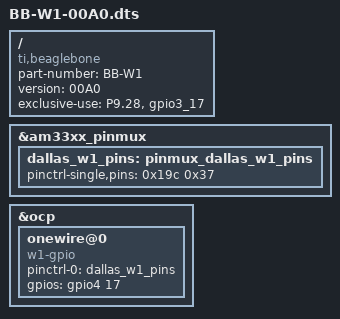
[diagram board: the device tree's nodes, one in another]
/dts-v1/;
/plugin/;

/ {
    /* 1-wire 18B20 temp sensor on P8_28 */
    compatible = "ti,beaglebone", "ti,beaglebone-black";

    part-number = "BB-W1";
    version = "00A0";

    /* state the resources this cape uses */
    exclusive-use =
        /* the pin header uses */
        "P9.28",
        /* the hardware IP uses */
        "gpio3_17";

    fragment@0 {
               target = <&am33xx_pinmux>;
               __overlay__ {
                    dallas_w1_pins: pinmux_dallas_w1_pins {
                        pinctrl-single,pins = <0x19c 0x37>; /* P9_28, Input + Pull up + MODE 7 */
                    };
               };
    };

    fragment@1 {
               target = <&ocp>;
               __overlay__ {
               onewire@0 {
                   compatible      = "w1-gpio";
                   pinctrl-names   = "default";
                   pinctrl-0       = <&dallas_w1_pins>;
                   status          = "okay";

                   gpios = <&gpio4 17 0>;
               };
         };
    };
};
